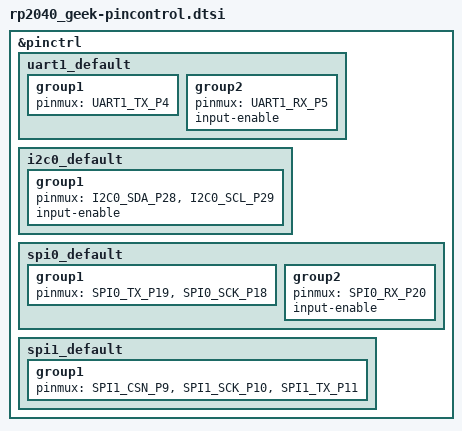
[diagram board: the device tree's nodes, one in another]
/*
 * Copyright (c) 2025 Jonas Berg
 *
 * SPDX-License-Identifier: Apache-2.0
 */

#include <dt-bindings/pinctrl/rpi-pico-rp2040-pinctrl.h>

&pinctrl {
	uart1_default: uart1_default {
		group1 {
			pinmux = <UART1_TX_P4>;
		};

		group2 {
			pinmux = <UART1_RX_P5>;
			input-enable;
		};
	};

	i2c0_default: i2c0_default {
		group1 {
			pinmux = <I2C0_SDA_P28>, <I2C0_SCL_P29>;
			input-enable;
		};
	};

	spi0_default: spi0_default {
		group1 {
			/* Pin GPIO23 is used as CS (no pinmux available) */
			pinmux = <SPI0_TX_P19>, <SPI0_SCK_P18>;
		};

		group2 {
			pinmux = <SPI0_RX_P20>;
			input-enable;
		};
	};

	spi1_default: spi1_default {
		group1 {
			pinmux = <SPI1_CSN_P9>, <SPI1_SCK_P10>, <SPI1_TX_P11>;
		};
	};
};
